# SPF1 register map
Vendor: Texas Instruments
Peripheral module from a debugger description file (folder am571x).
Registers are 32-bit, access per field, reset 0x0 unless marked. A register's access mark holds for its fields unless they carry their own. Offsets are as the file gives them; lines under a group give offsets from that group; [hi:lo] are bit positions; {n}, {i} and the like mark numbered series; 'fields as' and 'values as' point back to an identical list; <NAME> marks a mode.

## SPF1
0x00 SPF_IDVER ro reset not defined — SPF revision register
  [31:0] REVISION — SPF revision value
0x04 SPF_STATUS — Status register
  [0] SPF_BUSY rw — SPF is Busy/Idle, Busy Packet processing or logging in progress.
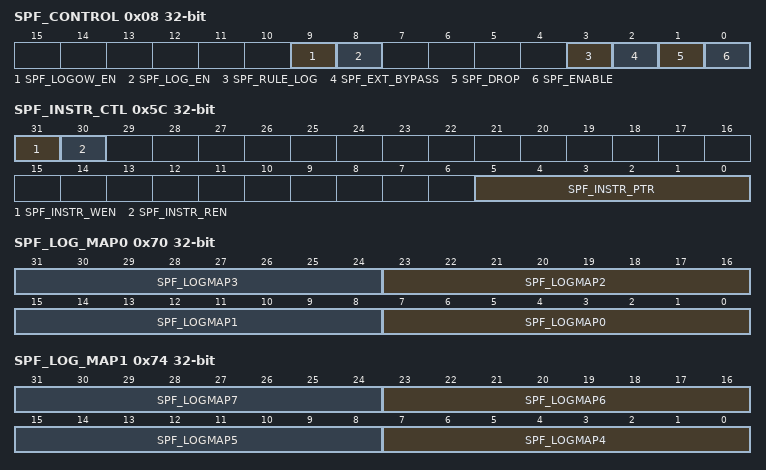
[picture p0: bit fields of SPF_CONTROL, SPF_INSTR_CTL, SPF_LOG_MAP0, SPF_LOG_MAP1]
0x08 SPF_CONTROL
  [9] SPF_LOGOW_EN rw — SPF Log Overwrite Enable. Setting this bit will cause SPF to overwrite previously logged data whether or not software has updated the software_working_pointer. Overwriting only occurs if there is new data but no space to write it in the space indicated by log_start_address and log_end_address.
  [8] SPF_LOG_EN rw — SPF Log Enable. Setting this bit will allow SPF to log information about dropped packets to memory.
  [3] SPF_RULE_LOG rw — SPF Rule Engine Log Enable. Setting this bit will allow SPF to log data from rule engine. The default is log data from extractor.
  [2] SPF_EXT_BYPASS rw — SPF Extractor Bypass Enable. The extractor will not provide any offset information to rule engine if this bit is set. The rule engine must load each of the base registers it intends to use to determine if the packet should be discarded.
  [1] SPF_DROP rw — SPF Drop Enable. This bit must be set to activate packet drops.
  [0] SPF_ENABLE rw — SPF Enable. This bit must be set to enable any operation in SPF. The SPF instruction memory can only be accessed by host processor when the spf_enable is deasserted. Once spf_enable is set, writing a zero to this bit will only take effect when spf_busy signal is low. This ensures that spf stops only on packet boundaries.
0x0C SPF_DROPCOUNT ro — Drop Count Register
  [23:0] SPF_DROPCNT — SPF Drop counter indicates the number of packets dropped so far. This counter does not roll over and must be cleared by writing 0x00FFFFFF.
0x10 SPF_SWRESET — Software Reset Register
  [0] SPF_SWRST rw — SPF Software reset bit can be set to initiate a software reset. It stays high until the reset has not completed, this reset clears all registers to default value.
0x14 SPF_PRESCALE — Rate Limit Prescale Register
  [19:0] SPF_PRESCALE rw — The MAIN clock is divided by this value for use in Rate Limiters. It is used to create rolling time intervals for use in rate limiting feature.
{0x18+4i} SPF_RATELIMi_{i} (i=0..3) — Rate Limit Register
  [7:0] SPF_RATELIM rw — SPF Rate Limit Register. The number of packets corresponding to a filter that will be allowed per unit time interval. The filters are programmed in the rule engine and time interval is determined by theSPF_PRESCALE register.
{0x1C+4i} SPF_CONSTj_{i} rw (i=0..7) — Constant Register
  [31:0] SPF_CONST — SPF Constant Register. The contents of this register are used as input to any instruction that references it.
0x50 SPF_INSTRW2 — Instruction Word 2 Register
  [13:0] SPF_INSTR_W2 rw — SPF Rule Engine Instruction Word [75:64] is read from or written to this field.
0x54 SPF_INSTRW1 rw — Instruction Word 1 Register
  [31:0] SPF_INSTR_W1 — SPF Rule Engine Instruction Word [63:32] is read from or written to this field.
0x58 SPF_INSTRW0 rw — Instruction Word 0 Register
  [31:0] SPF_INSTR_W0 — SPF Rule Engine Instruction Word [31:0] is read from or written to this field.
0x5C SPF_INSTR_CTL — Instruction Control Register
  [31] SPF_INSTR_WEN wo — SPF Write enable bit specifies whether a write operation is to be performed. To read or write instructions, spf processing must be stopped. When the rule engine is processing instructions, the instruction memory cannot be accessed. This bit is set to perform a write and the data in the SPF_INSTR_W2, SPF_INSTR_W1 and SPF_INSTR_W0 registers is written to the instruction RAM at address specified in the SPF_INSTR_PTR field. This bit is always read as zero.
  [30] SPF_INSTR_REN wo — SPF Read enable bit specifies whether a read operation is to be performed. This bit is set to perform a read and read data is available in the SPF_INSTR_W2, SPF_INSTR_W1 and SPF_INSTR_W0 registers once read operation has completed. This bit is always read as zero.
  [5:0] SPF_INSTR_PTR rw — The address in the instruction memory that is to be accessed.
0x60 SPF_LOG_BEGIN rw — Log Begin Address Register
  [31:0] SPF_LOG_BEGIN — SPF starts to write log data to memory starting from address given in this field.
0x64 SPF_LOG_END rw reset 0x1000 — Log End Address Register
  [31:0] SPF_LOG_END — This register along withSPF_LOG_BEGIN register defines the memory range for writing log data, the range(SPF_LOG_END SPF_LOG_BEGIN) should be multiple of 4 words(32 bits), as this is a look ahead register therefore the value progammed should be next word address. (i.e. last word address + 4).
0x68 SPF_LOG_HWPTR rw — Log Hardware Pointer Register
  [31:0] SPF_LOG_HWPTR — This register indicated the address of next location in memory that the SPF will log information to.
0x6C SPF_LOG_SWPTR rw — Log Software Pointer Register
  [31:0] SPF_LOG_SWPTR — This register specifies the address where software shall do next read, software must inform SPF about memory roll over by writingSPF_LOG_END into this register.
0x70 SPF_LOG_MAP0 rw — Filter Code Map Register 0
  [8n+7:8n] SPF_LOGMAP{n} (n=0..3) — Mapping of drop code {n} to log threshold {n}
0x74 SPF_LOG_MAP1 rw — Filter Code Map Register 1
  [8n-25:8n-32] SPF_LOGMAP{n} (n=4..7) — Mapping of drop code {n} to log threshold {n}
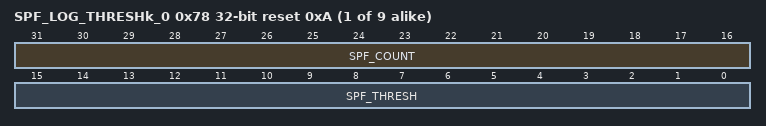
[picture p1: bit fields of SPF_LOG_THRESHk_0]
{0x78+4i} SPF_LOG_THRESHk_{i} reset 0xA (i=0..8) — Log Threshold and Count Register
  [31:16] SPF_COUNT ro — Number of packets dropped for drop code k (8 is default)
  [15:0] SPF_THRESH rw — Number of packets to be dropped before logging starts
0x9C SPF_INTCNT — Interrupt Frequency Control Register
  [4:0] SPF_INTCNT rw — Number of time thresholds must be met before a drop interrupt is triggered.
0xA0 SPF_INT_RAW — Raw Interrupt Status register
  [0] SPF_INT_RAW rw — Status of Raw interrupt signal
0xA4 SPF_INT_MASKED — Interrupt Status register
  [0] SPF_INT_MASKED rw — Status of interrupt signal with mask
0xA8 SPF_MASK_SET — Interrupt Mask Set Register
  [0] SPF_MASKSET rw — Write a 1 to this bit to enable the interrupt.
0xAC SPF_MASK_CLR — Interrupt Mask Clear Register
  [0] SPF_MASKCLR rw — Write a 1 to this bit to disable the interrupt.
